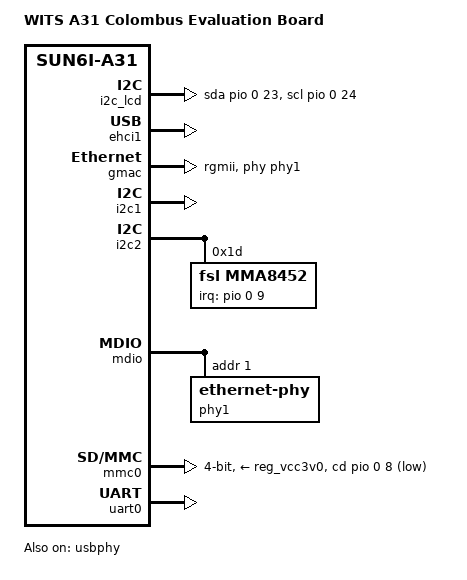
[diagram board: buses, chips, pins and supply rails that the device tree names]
/dts-v1/;
#include "sun6i-a31.dtsi"
#include "sunxi-common-regulators.dtsi"
#include <dt-bindings/gpio/gpio.h>
/ {
	model = "WITS A31 Colombus Evaluation Board";
	compatible = "wits,colombus", "allwinner,sun6i-a31";
	aliases {
		serial0 = &uart0;
	};
	chosen {
		stdout-path = "serial0:115200n8";
	};
	i2c_lcd: i2c {
		compatible = "i2c-gpio";
		sda-gpios = <&pio 0 23 (GPIO_ACTIVE_HIGH | GPIO_PULL_UP)>;  
		scl-gpios = <&pio 0 24 (GPIO_ACTIVE_HIGH | GPIO_PULL_UP)>;  
		i2c-gpio,delay-us = <5>;
	};
};
&ehci1 {
	status = "okay";
};
&gmac {
	pinctrl-names = "default";
	pinctrl-0 = <&gmac_rgmii_pins>;
	phy-handle = <&phy1>;
	phy-mode = "rgmii";
	status = "okay";
};
&i2c0 {
	status = "fail";
};
&i2c1 {
	status = "okay";
};
&i2c2 {
	status = "okay";
	mma8452: mma8452@1d {
		compatible = "fsl,mma8452";
		reg = <0x1d>;
		interrupt-parent = <&pio>;
		interrupts = <0 9 IRQ_TYPE_LEVEL_LOW>;  
	};
};
&mdio {
	phy1: ethernet-phy@1 {
		reg = <1>;
	};
};
&mmc0 {
	vmmc-supply = <&reg_vcc3v0>;
	bus-width = <4>;
	cd-gpios = <&pio 0 8 GPIO_ACTIVE_LOW>;  
	status = "okay";
};
&reg_usb2_vbus {
	gpio = <&pio 7 24 GPIO_ACTIVE_HIGH>;
	status = "okay";
};
&uart0 {
	pinctrl-names = "default";
	pinctrl-0 = <&uart0_ph_pins>;
	status = "okay";
};
&usbphy {
	usb2_vbus-supply = <&reg_usb2_vbus>;
	status = "okay";
};
